VERSION ""

NS_ :

BS_:

BU_: ECU PD16A KEYPAD

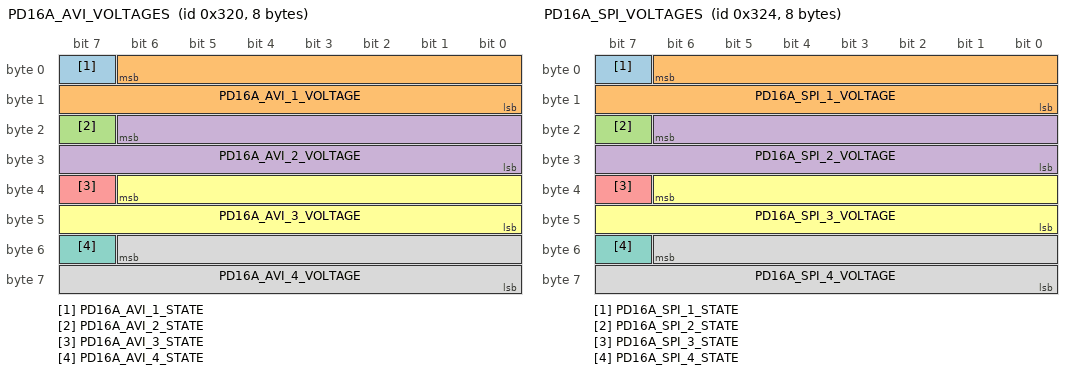
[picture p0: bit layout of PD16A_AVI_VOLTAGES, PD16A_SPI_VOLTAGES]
BO_ 800 PD16A_AVI_VOLTAGES: 8 PD16A
 SG_ PD16A_AVI_1_STATE : 7|1@0+ (1,0) [0|0] "" ECU
 SG_ PD16A_AVI_1_VOLTAGE : 6|15@0+ (0.001,0) [0|32.767] "V" ECU
 SG_ PD16A_AVI_2_STATE : 23|1@0+ (1,0) [0|0] "" ECU
 SG_ PD16A_AVI_2_VOLTAGE : 22|15@0+ (0.001,0) [0|32.767] "V" ECU
 SG_ PD16A_AVI_3_STATE : 39|1@0+ (1,0) [0|0] "" ECU
 SG_ PD16A_AVI_3_VOLTAGE : 38|15@0+ (0.001,0) [0|32.767] "V" ECU
 SG_ PD16A_AVI_4_STATE : 55|1@0+ (1,0) [0|0] "" ECU
 SG_ PD16A_AVI_4_VOLTAGE : 54|15@0+ (0.001,0) [0|32.767] "V" ECU

BO_ 804 PD16A_SPI_VOLTAGES: 8 PD16A
 SG_ PD16A_SPI_1_STATE : 7|1@0+ (1,0) [0|0] "" ECU
 SG_ PD16A_SPI_1_VOLTAGE : 6|15@0+ (0.001,0) [0|32.767] "V" ECU
 SG_ PD16A_SPI_2_STATE : 23|1@0+ (1,0) [0|0] "" ECU
 SG_ PD16A_SPI_2_VOLTAGE : 22|15@0+ (0.001,0) [0|32.767] "V" ECU
 SG_ PD16A_SPI_3_STATE : 39|1@0+ (1,0) [0|0] "" ECU
 SG_ PD16A_SPI_3_VOLTAGE : 38|15@0+ (0.001,0) [0|32.767] "V" ECU
 SG_ PD16A_SPI_4_STATE : 55|1@0+ (1,0) [0|0] "" ECU
 SG_ PD16A_SPI_4_VOLTAGE : 54|15@0+ (0.001,0) [0|32.767] "V" ECU

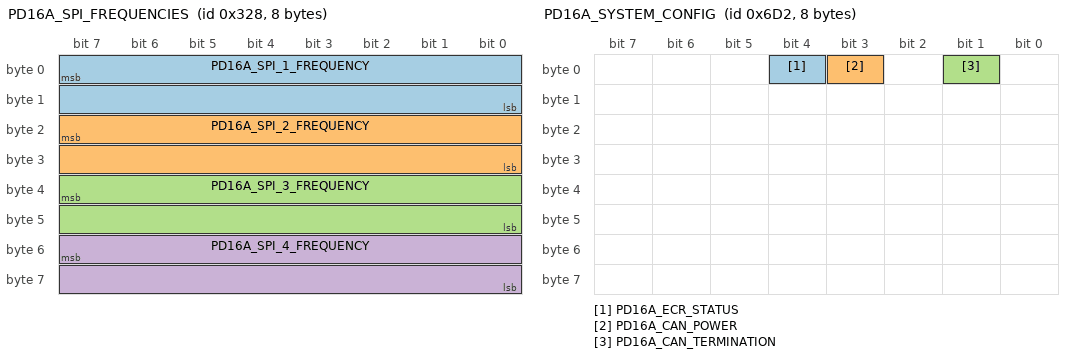
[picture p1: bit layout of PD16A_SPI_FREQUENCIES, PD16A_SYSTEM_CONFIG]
BO_ 808 PD16A_SPI_FREQUENCIES: 8 PD16A
 SG_ PD16A_SPI_1_FREQUENCY : 7|16@0+ (0.25,0) [0|16383.8] "Hz" ECU
 SG_ PD16A_SPI_2_FREQUENCY : 23|16@0+ (0.25,0) [0|16383.8] "Hz" ECU
 SG_ PD16A_SPI_3_FREQUENCY : 39|16@0+ (0.25,0) [0|16383.8] "Hz" ECU
 SG_ PD16A_SPI_4_FREQUENCY : 55|16@0+ (0.25,0) [0|16383.8] "Hz" ECU

BO_ 1744 PD16A_OUTPUT_COMMANDS: 8 ECU
 SG_ PD16A_OUTPUT_CMD_MUX M : 7|8@0+ (1,0) [0|255] "" PD16A
 SG_ PD16A_HCO25_1_CMD_DUTY m0 : 15|16@0+ (0.1,0) [0|100] "%" PD16A
 SG_ PD16A_HCO25_1_CMD_FREQ m0 : 31|16@0+ (1,0) [0|65535] "Hz" PD16A
 SG_ PD16A_HCO25_2_CMD_DUTY m1 : 15|16@0+ (0.1,0) [0|100] "%" PD16A
 SG_ PD16A_HCO25_2_CMD_FREQ m1 : 31|16@0+ (1,0) [0|65535] "Hz" PD16A
 SG_ PD16A_HCO25_3_CMD_DUTY m2 : 15|16@0+ (0.1,0) [0|100] "%" PD16A
 SG_ PD16A_HCO25_3_CMD_FREQ m2 : 31|16@0+ (1,0) [0|65535] "Hz" PD16A
 SG_ PD16A_HCO25_4_CMD_DUTY m3 : 15|16@0+ (0.1,0) [0|100] "%" PD16A
 SG_ PD16A_HCO25_4_CMD_FREQ m3 : 31|16@0+ (1,0) [0|65535] "Hz" PD16A
 SG_ PD16A_HCO8_1_CMD_DUTY m32 : 15|16@0+ (0.1,0) [0|100] "%" PD16A
 SG_ PD16A_HCO8_1_CMD_FREQ m32 : 31|16@0+ (1,0) [0|65535] "Hz" PD16A
 SG_ PD16A_HCO8_2_CMD_DUTY m33 : 15|16@0+ (0.1,0) [0|100] "%" PD16A
 SG_ PD16A_HCO8_2_CMD_FREQ m33 : 31|16@0+ (1,0) [0|65535] "Hz" PD16A
 SG_ PD16A_HCO8_3_CMD_DUTY m34 : 15|16@0+ (0.1,0) [0|100] "%" PD16A
 SG_ PD16A_HCO8_3_CMD_FREQ m34 : 31|16@0+ (1,0) [0|65535] "Hz" PD16A
 SG_ PD16A_HCO8_4_CMD_DUTY m35 : 15|16@0+ (0.1,0) [0|100] "%" PD16A
 SG_ PD16A_HCO8_4_CMD_FREQ m35 : 31|16@0+ (1,0) [0|65535] "Hz" PD16A
 SG_ PD16A_HCO8_5_CMD_DUTY m36 : 15|16@0+ (0.1,0) [0|100] "%" PD16A
 SG_ PD16A_HCO8_5_CMD_FREQ m36 : 31|16@0+ (1,0) [0|65535] "Hz" PD16A
 SG_ PD16A_HCO8_6_CMD_DUTY m37 : 15|16@0+ (0.1,0) [0|100] "%" PD16A
 SG_ PD16A_HCO8_6_CMD_FREQ m37 : 31|16@0+ (1,0) [0|65535] "Hz" PD16A
 SG_ PD16A_HCO8_7_CMD_DUTY m38 : 15|16@0+ (0.1,0) [0|100] "%" PD16A
 SG_ PD16A_HCO8_7_CMD_FREQ m38 : 31|16@0+ (1,0) [0|65535] "Hz" PD16A
 SG_ PD16A_HCO8_8_CMD_DUTY m39 : 15|16@0+ (0.1,0) [0|100] "%" PD16A
 SG_ PD16A_HCO8_8_CMD_FREQ m39 : 31|16@0+ (1,0) [0|65535] "Hz" PD16A
 SG_ PD16A_HCO8_9_CMD_DUTY m40 : 15|16@0+ (0.1,0) [0|100] "%" PD16A
 SG_ PD16A_HCO8_9_CMD_FREQ m40 : 31|16@0+ (1,0) [0|65535] "Hz" PD16A
 SG_ PD16A_HCO8_10_CMD_DUTY m41 : 15|16@0+ (0.1,0) [0|100] "%" PD16A
 SG_ PD16A_HCO8_10_CMD_FREQ m41 : 31|16@0+ (1,0) [0|65535] "Hz" PD16A
 SG_ PD16A_HBO_1_CMD_DUTY m64 : 15|16@0+ (0.1,0) [0|100] "%" PD16A
 SG_ PD16A_HBO_1_CMD_FREQ m64 : 31|16@0+ (1,0) [0|65535] "Hz" PD16A
 SG_ PD16A_HBO_1_TARGET_CURRENT m64 : 47|16@0+ (0.001,0) [0|65.535] "A" PD16A
 SG_ PD16A_HBO_2_CMD_DUTY m65 : 15|16@0+ (0.1,0) [0|100] "%" PD16A
 SG_ PD16A_HBO_2_CMD_FREQ m65 : 31|16@0+ (1,0) [0|65535] "Hz" PD16A
 SG_ PD16A_HBO_2_TARGET_CURRENT m65 : 47|16@0+ (0.001,0) [0|65.535] "A" PD16A

BO_ 1745 PD16A_IO_CONFIG: 8 ECU
 SG_ PD16A_IO_CFG_MUX M : 7|8@0+ (1,0) [0|255] "" PD16A
 SG_ PD16A_HCO25_1_CFG_RETRIES m0 : 15|3@0+ (1,0) [0|7] "" PD16A
 SG_ PD16A_HCO25_1_CFG_DRIVE_TYPE m0 : 12|2@0+ (1,0) [0|3] "" PD16A
 SG_ PD16A_HCO25_1_CFG_SAFE_STATE m0 : 10|2@0+ (1,0) [0|3] "" PD16A
 SG_ PD16A_HCO25_1_CFG_ACTIVE_STATE m0 : 8|1@0+ (1,0) [0|0] "" PD16A
 SG_ PD16A_HCO25_1_CFG_RETRY_DELAY m0 : 23|8@0+ (1,0) [0|240] "s" PD16A
 SG_ PD16A_HCO25_1_CFG_FUSE_CURRENT m0 : 31|8@0+ (0.2,0) [0|50] "A" PD16A
 SG_ PD16A_HCO25_1_CFG_SS_CURRENT m0 : 39|8@0+ (0.2,0) [0|50] "A" PD16A
 SG_ PD16A_HCO25_1_CFG_SS_DURATION m0 : 47|8@0+ (0.1,0) [0|25] "s" PD16A
 SG_ PD16A_HCO25_2_CFG_RETRIES m1 : 15|3@0+ (1,0) [0|7] "" PD16A
 SG_ PD16A_HCO25_2_CFG_DRIVE_TYPE m1 : 12|2@0+ (1,0) [0|3] "" PD16A
 SG_ PD16A_HCO25_2_CFG_SAFE_STATE m1 : 10|2@0+ (1,0) [0|3] "" PD16A
 SG_ PD16A_HCO25_2_CFG_ACTIVE_STATE m1 : 8|1@0+ (1,0) [0|0] "" PD16A
 SG_ PD16A_HCO25_2_CFG_RETRY_DELAY m1 : 23|8@0+ (1,0) [0|240] "s" PD16A
 SG_ PD16A_HCO25_2_CFG_FUSE_CURRENT m1 : 31|8@0+ (0.2,0) [0|50] "A" PD16A
 SG_ PD16A_HCO25_2_CFG_SS_CURRENT m1 : 39|8@0+ (0.2,0) [0|50] "A" PD16A
 SG_ PD16A_HCO25_2_CFG_SS_DURATION m1 : 47|8@0+ (0.1,0) [0|25] "s" PD16A
 SG_ PD16A_HCO25_3_CFG_RETRIES m2 : 15|3@0+ (1,0) [0|7] "" PD16A
 SG_ PD16A_HCO25_3_CFG_DRIVE_TYPE m2 : 12|2@0+ (1,0) [0|3] "" PD16A
 SG_ PD16A_HCO25_3_CFG_SAFE_STATE m2 : 10|2@0+ (1,0) [0|3] "" PD16A
 SG_ PD16A_HCO25_3_CFG_ACTIVE_STATE m2 : 8|1@0+ (1,0) [0|0] "" PD16A
 SG_ PD16A_HCO25_3_CFG_RETRY_DELAY m2 : 23|8@0+ (1,0) [0|240] "s" PD16A
 SG_ PD16A_HCO25_3_CFG_FUSE_CURRENT m2 : 31|8@0+ (0.2,0) [0|50] "A" PD16A
 SG_ PD16A_HCO25_3_CFG_SS_CURRENT m2 : 39|8@0+ (0.2,0) [0|50] "A" PD16A
 SG_ PD16A_HCO25_3_CFG_SS_DURATION m2 : 47|8@0+ (0.1,0) [0|25] "s" PD16A
 SG_ PD16A_HCO25_4_CFG_RETRIES m3 : 15|3@0+ (1,0) [0|7] "" PD16A
 SG_ PD16A_HCO25_4_CFG_DRIVE_TYPE m3 : 12|2@0+ (1,0) [0|3] "" PD16A
 SG_ PD16A_HCO25_4_CFG_SAFE_STATE m3 : 10|2@0+ (1,0) [0|3] "" PD16A
 SG_ PD16A_HCO25_4_CFG_ACTIVE_STATE m3 : 8|1@0+ (1,0) [0|0] "" PD16A
 SG_ PD16A_HCO25_4_CFG_RETRY_DELAY m3 : 23|8@0+ (1,0) [0|240] "s" PD16A
 SG_ PD16A_HCO25_4_CFG_FUSE_CURRENT m3 : 31|8@0+ (0.2,0) [0|50] "A" PD16A
 SG_ PD16A_HCO25_4_CFG_SS_CURRENT m3 : 39|8@0+ (0.2,0) [0|50] "A" PD16A
 SG_ PD16A_HCO25_4_CFG_SS_DURATION m3 : 47|8@0+ (0.1,0) [0|25] "s" PD16A
 SG_ PD16A_HCO8_1_CFG_RETRIES m32 : 15|3@0+ (1,0) [0|7] "" PD16A
 SG_ PD16A_HCO8_1_CFG_DRIVE_TYPE m32 : 12|2@0+ (1,0) [0|3] "" PD16A
 SG_ PD16A_HCO8_1_CFG_SAFE_STATE m32 : 10|2@0+ (1,0) [0|3] "" PD16A
 SG_ PD16A_HCO8_1_CFG_ACTIVE_STATE m32 : 8|1@0+ (1,0) [0|0] "" PD16A
 SG_ PD16A_HCO8_1_CFG_RETRY_DELAY m32 : 23|8@0+ (1,0) [0|240] "s" PD16A
 SG_ PD16A_HCO8_1_CFG_FUSE_CURRENT m32 : 31|8@0+ (0.2,0) [0|50] "A" PD16A
 SG_ PD16A_HCO8_2_CFG_RETRIES m33 : 15|3@0+ (1,0) [0|7] "" PD16A
 SG_ PD16A_HCO8_2_CFG_DRIVE_TYPE m33 : 12|2@0+ (1,0) [0|3] "" PD16A
 SG_ PD16A_HCO8_2_CFG_SAFE_STATE m33 : 10|2@0+ (1,0) [0|3] "" PD16A
 SG_ PD16A_HCO8_2_CFG_ACTIVE_STATE m33 : 8|1@0+ (1,0) [0|0] "" PD16A
 SG_ PD16A_HCO8_2_CFG_RETRY_DELAY m33 : 23|8@0+ (1,0) [0|240] "s" PD16A
 SG_ PD16A_HCO8_2_CFG_FUSE_CURRENT m33 : 31|8@0+ (0.2,0) [0|50] "A" PD16A
 SG_ PD16A_HCO8_3_CFG_RETRIES m34 : 15|3@0+ (1,0) [0|7] "" PD16A
 SG_ PD16A_HCO8_3_CFG_DRIVE_TYPE m34 : 12|2@0+ (1,0) [0|3] "" PD16A
 SG_ PD16A_HCO8_3_CFG_SAFE_STATE m34 : 10|2@0+ (1,0) [0|3] "" PD16A
 SG_ PD16A_HCO8_3_CFG_ACTIVE_STATE m34 : 8|1@0+ (1,0) [0|0] "" PD16A
 SG_ PD16A_HCO8_3_CFG_RETRY_DELAY m34 : 23|8@0+ (1,0) [0|240] "s" PD16A
 SG_ PD16A_HCO8_3_CFG_FUSE_CURRENT m34 : 31|8@0+ (0.2,0) [0|50] "A" PD16A
 SG_ PD16A_HCO8_4_CFG_RETRIES m35 : 15|3@0+ (1,0) [0|7] "" PD16A
 SG_ PD16A_HCO8_4_CFG_DRIVE_TYPE m35 : 12|2@0+ (1,0) [0|3] "" PD16A
 SG_ PD16A_HCO8_4_CFG_SAFE_STATE m35 : 10|2@0+ (1,0) [0|3] "" PD16A
 SG_ PD16A_HCO8_4_CFG_ACTIVE_STATE m35 : 8|1@0+ (1,0) [0|0] "" PD16A
 SG_ PD16A_HCO8_4_CFG_RETRY_DELAY m35 : 23|8@0+ (1,0) [0|240] "s" PD16A
 SG_ PD16A_HCO8_4_CFG_FUSE_CURRENT m35 : 31|8@0+ (0.2,0) [0|50] "A" PD16A
 SG_ PD16A_HCO8_5_CFG_RETRIES m36 : 15|3@0+ (1,0) [0|7] "" PD16A
 SG_ PD16A_HCO8_5_CFG_DRIVE_TYPE m36 : 12|2@0+ (1,0) [0|3] "" PD16A
 SG_ PD16A_HCO8_5_CFG_SAFE_STATE m36 : 10|2@0+ (1,0) [0|3] "" PD16A
 SG_ PD16A_HCO8_5_CFG_ACTIVE_STATE m36 : 8|1@0+ (1,0) [0|0] "" PD16A
 SG_ PD16A_HCO8_5_CFG_RETRY_DELAY m36 : 23|8@0+ (1,0) [0|240] "s" PD16A
 SG_ PD16A_HCO8_5_CFG_FUSE_CURRENT m36 : 31|8@0+ (0.2,0) [0|50] "A" PD16A
 SG_ PD16A_HCO8_6_CFG_RETRIES m37 : 15|3@0+ (1,0) [0|7] "" PD16A
 SG_ PD16A_HCO8_6_CFG_DRIVE_TYPE m37 : 12|2@0+ (1,0) [0|3] "" PD16A
 SG_ PD16A_HCO8_6_CFG_SAFE_STATE m37 : 10|2@0+ (1,0) [0|3] "" PD16A
 SG_ PD16A_HCO8_6_CFG_ACTIVE_STATE m37 : 8|1@0+ (1,0) [0|0] "" PD16A
 SG_ PD16A_HCO8_6_CFG_RETRY_DELAY m37 : 23|8@0+ (1,0) [0|240] "s" PD16A
 SG_ PD16A_HCO8_6_CFG_FUSE_CURRENT m37 : 31|8@0+ (0.2,0) [0|50] "A" PD16A
 SG_ PD16A_HCO8_7_CFG_RETRIES m38 : 15|3@0+ (1,0) [0|7] "" PD16A
 SG_ PD16A_HCO8_7_CFG_DRIVE_TYPE m38 : 12|2@0+ (1,0) [0|3] "" PD16A
 SG_ PD16A_HCO8_7_CFG_SAFE_STATE m38 : 10|2@0+ (1,0) [0|3] "" PD16A
 SG_ PD16A_HCO8_7_CFG_ACTIVE_STATE m38 : 8|1@0+ (1,0) [0|0] "" PD16A
 SG_ PD16A_HCO8_7_CFG_RETRY_DELAY m38 : 23|8@0+ (1,0) [0|240] "s" PD16A
 SG_ PD16A_HCO8_7_CFG_FUSE_CURRENT m38 : 31|8@0+ (0.2,0) [0|50] "A" PD16A
 SG_ PD16A_HCO8_8_CFG_RETRIES m39 : 15|3@0+ (1,0) [0|7] "" PD16A
 SG_ PD16A_HCO8_8_CFG_DRIVE_TYPE m39 : 12|2@0+ (1,0) [0|3] "" PD16A
 SG_ PD16A_HCO8_8_CFG_SAFE_STATE m39 : 10|2@0+ (1,0) [0|3] "" PD16A
 SG_ PD16A_HCO8_8_CFG_ACTIVE_STATE m39 : 8|1@0+ (1,0) [0|0] "" PD16A
 SG_ PD16A_HCO8_8_CFG_RETRY_DELAY m39 : 23|8@0+ (1,0) [0|240] "s" PD16A
 SG_ PD16A_HCO8_8_CFG_FUSE_CURRENT m39 : 31|8@0+ (0.2,0) [0|50] "A" PD16A
 SG_ PD16A_HCO8_9_CFG_RETRIES m40 : 15|3@0+ (1,0) [0|7] "" PD16A
 SG_ PD16A_HCO8_9_CFG_DRIVE_TYPE m40 : 12|2@0+ (1,0) [0|3] "" PD16A
 SG_ PD16A_HCO8_9_CFG_SAFE_STATE m40 : 10|2@0+ (1,0) [0|3] "" PD16A
 SG_ PD16A_HCO8_9_CFG_ACTIVE_STATE m40 : 8|1@0+ (1,0) [0|0] "" PD16A
 SG_ PD16A_HCO8_9_CFG_RETRY_DELAY m40 : 23|8@0+ (1,0) [0|240] "s" PD16A
 SG_ PD16A_HCO8_9_CFG_FUSE_CURRENT m40 : 31|8@0+ (0.2,0) [0|50] "A" PD16A
 SG_ PD16A_HCO8_10_CFG_RETRIES m41 : 15|3@0+ (1,0) [0|7] "" PD16A
 SG_ PD16A_HCO8_10_CFG_DRIVE_TYPE m41 : 12|2@0+ (1,0) [0|3] "" PD16A
 SG_ PD16A_HCO8_10_CFG_SAFE_STATE m41 : 10|2@0+ (1,0) [0|3] "" PD16A
 SG_ PD16A_HCO8_10_CFG_ACTIVE_STATE m41 : 8|1@0+ (1,0) [0|0] "" PD16A
 SG_ PD16A_HCO8_10_CFG_RETRY_DELAY m41 : 23|8@0+ (1,0) [0|240] "s" PD16A
 SG_ PD16A_HCO8_10_CFG_FUSE_CURRENT m41 : 31|8@0+ (0.2,0) [0|50] "A" PD16A
 SG_ PD16A_HBO_1_CFG_RETRIES m64 : 15|3@0+ (1,0) [0|7] "" PD16A
 SG_ PD16A_HBO_1_CFG_DRIVE_TYPE m64 : 12|2@0+ (1,0) [0|3] "" PD16A
 SG_ PD16A_HBO_1_CFG_SAFE_STATE m64 : 10|2@0+ (1,0) [0|3] "" PD16A
 SG_ PD16A_HBO_1_CFG_ACTIVE_STATE m64 : 8|1@0+ (1,0) [0|0] "" PD16A
 SG_ PD16A_HBO_1_CFG_RETRY_DELAY m64 : 23|8@0+ (1,0) [0|240] "s" PD16A
 SG_ PD16A_HBO_1_CFG_CONTROL_METHOD m64 : 24|1@0+ (1,0) [0|0] "" PD16A
 SG_ PD16A_HBO_1_CFG_FUSE_CURRENT m64 : 39|8@0+ (0.2,0) [0|50] "A" PD16A
 SG_ PD16A_HBO_2_CFG_RETRIES m65 : 15|3@0+ (1,0) [0|7] "" PD16A
 SG_ PD16A_HBO_2_CFG_DRIVE_TYPE m65 : 12|2@0+ (1,0) [0|3] "" PD16A
 SG_ PD16A_HBO_2_CFG_SAFE_STATE m65 : 10|2@0+ (1,0) [0|3] "" PD16A
 SG_ PD16A_HBO_2_CFG_ACTIVE_STATE m65 : 8|1@0+ (1,0) [0|0] "" PD16A
 SG_ PD16A_HBO_2_CFG_RETRY_DELAY m65 : 23|8@0+ (1,0) [0|240] "s" PD16A
 SG_ PD16A_HBO_2_CFG_CONTROL_METHOD m65 : 24|1@0+ (1,0) [0|0] "" PD16A
 SG_ PD16A_HBO_2_CFG_FUSE_CURRENT m65 : 39|8@0+ (0.2,0) [0|50] "A" PD16A
 SG_ PD16A_SPI_1_CFG_PIN_MODE m96 : 15|2@0+ (1,0) [0|2] "" PD16A
 SG_ PD16A_SPI_1_CFG_STARTUP_STATE m96 : 13|2@0+ (1,0) [0|2] "" PD16A
 SG_ PD16A_SPI_1_CFG_INPUT_MODE m96 : 11|1@0+ (1,0) [0|0] "" PD16A
 SG_ PD16A_SPI_1_CFG_PULLUP m96 : 10|2@0+ (1,0) [0|1] "" PD16A
 SG_ PD16A_SPI_1_CFG_EDGE_SELECT m96 : 8|1@0+ (1,0) [0|0] "" PD16A
 SG_ PD16A_SPI_1_CFG_UPPER_THRESHOLD m96 : 39|16@0+ (0.001,0) [0|65.535] "V" PD16A
 SG_ PD16A_SPI_1_CFG_GLITCH_FILTER m96 : 55|16@0+ (1,0) [0|500] "us" PD16A
 SG_ PD16A_SPI_2_CFG_PIN_MODE m97 : 15|2@0+ (1,0) [0|2] "" PD16A
 SG_ PD16A_SPI_2_CFG_STARTUP_STATE m97 : 13|2@0+ (1,0) [0|2] "" PD16A
 SG_ PD16A_SPI_2_CFG_INPUT_MODE m97 : 11|1@0+ (1,0) [0|0] "" PD16A
 SG_ PD16A_SPI_2_CFG_PULLUP m97 : 10|2@0+ (1,0) [0|1] "" PD16A
 SG_ PD16A_SPI_2_CFG_EDGE_SELECT m97 : 8|1@0+ (1,0) [0|0] "" PD16A
 SG_ PD16A_SPI_2_CFG_UPPER_THRESHOLD m97 : 39|16@0+ (0.001,0) [0|65.535] "V" PD16A
 SG_ PD16A_SPI_2_CFG_GLITCH_FILTER m97 : 55|16@0+ (1,0) [0|500] "us" PD16A
 SG_ PD16A_SPI_3_CFG_PIN_MODE m98 : 15|2@0+ (1,0) [0|2] "" PD16A
 SG_ PD16A_SPI_3_CFG_STARTUP_STATE m98 : 13|2@0+ (1,0) [0|2] "" PD16A
 SG_ PD16A_SPI_3_CFG_INPUT_MODE m98 : 11|1@0+ (1,0) [0|0] "" PD16A
 SG_ PD16A_SPI_3_CFG_PULLUP m98 : 10|2@0+ (1,0) [0|1] "" PD16A
 SG_ PD16A_SPI_3_CFG_EDGE_SELECT m98 : 8|1@0+ (1,0) [0|0] "" PD16A
 SG_ PD16A_SPI_3_CFG_UPPER_THRESHOLD m98 : 39|16@0+ (0.001,0) [0|65.535] "V" PD16A
 SG_ PD16A_SPI_3_CFG_GLITCH_FILTER m98 : 55|16@0+ (1,0) [0|500] "us" PD16A
 SG_ PD16A_SPI_4_CFG_PIN_MODE m99 : 15|2@0+ (1,0) [0|2] "" PD16A
 SG_ PD16A_SPI_4_CFG_STARTUP_STATE m99 : 13|2@0+ (1,0) [0|2] "" PD16A
 SG_ PD16A_SPI_4_CFG_INPUT_MODE m99 : 11|1@0+ (1,0) [0|0] "" PD16A
 SG_ PD16A_SPI_4_CFG_PULLUP m99 : 10|2@0+ (1,0) [0|1] "" PD16A
 SG_ PD16A_SPI_4_CFG_EDGE_SELECT m99 : 8|1@0+ (1,0) [0|0] "" PD16A
 SG_ PD16A_SPI_4_CFG_UPPER_THRESHOLD m99 : 39|16@0+ (0.001,0) [0|65.535] "V" PD16A
 SG_ PD16A_SPI_4_CFG_GLITCH_FILTER m99 : 55|16@0+ (1,0) [0|500] "us" PD16A
 SG_ PD16A_AVI_1_CFG_STARTUP_STATE m128 : 13|2@0+ (1,0) [0|2] "" PD16A
 SG_ PD16A_AVI_1_CFG_INPUT_MODE m128 : 11|1@0+ (1,0) [0|0] "" PD16A
 SG_ PD16A_AVI_1_CFG_PULLUP m128 : 10|2@0+ (1,0) [0|2] "" PD16A
 SG_ PD16A_AVI_1_CFG_ON_THRESHOLD m128 : 23|16@0+ (0.001,0) [0|65.535] "V" PD16A
 SG_ PD16A_AVI_1_CFG_OFF_THRESHOLD m128 : 39|16@0+ (0.001,0) [0|65.535] "V" PD16A
 SG_ PD16A_AVI_2_CFG_STARTUP_STATE m129 : 13|2@0+ (1,0) [0|2] "" PD16A
 SG_ PD16A_AVI_2_CFG_INPUT_MODE m129 : 11|1@0+ (1,0) [0|0] "" PD16A
 SG_ PD16A_AVI_2_CFG_PULLUP m129 : 10|2@0+ (1,0) [0|2] "" PD16A
 SG_ PD16A_AVI_2_CFG_ON_THRESHOLD m129 : 23|16@0+ (0.001,0) [0|65.535] "V" PD16A
 SG_ PD16A_AVI_2_CFG_OFF_THRESHOLD m129 : 39|16@0+ (0.001,0) [0|65.535] "V" PD16A
 SG_ PD16A_AVI_3_CFG_STARTUP_STATE m130 : 13|2@0+ (1,0) [0|2] "" PD16A
 SG_ PD16A_AVI_3_CFG_INPUT_MODE m130 : 11|1@0+ (1,0) [0|0] "" PD16A
 SG_ PD16A_AVI_3_CFG_PULLUP m130 : 10|2@0+ (1,0) [0|2] "" PD16A
 SG_ PD16A_AVI_3_CFG_ON_THRESHOLD m130 : 23|16@0+ (0.001,0) [0|65.535] "V" PD16A
 SG_ PD16A_AVI_3_CFG_OFF_THRESHOLD m130 : 39|16@0+ (0.001,0) [0|65.535] "V" PD16A
 SG_ PD16A_AVI_4_CFG_STARTUP_STATE m131 : 13|2@0+ (1,0) [0|2] "" PD16A
 SG_ PD16A_AVI_4_CFG_INPUT_MODE m131 : 11|1@0+ (1,0) [0|0] "" PD16A
 SG_ PD16A_AVI_4_CFG_PULLUP m131 : 10|2@0+ (1,0) [0|2] "" PD16A
 SG_ PD16A_AVI_4_CFG_ON_THRESHOLD m131 : 23|16@0+ (0.001,0) [0|65.535] "V" PD16A
 SG_ PD16A_AVI_4_CFG_OFF_THRESHOLD m131 : 39|16@0+ (0.001,0) [0|65.535] "V" PD16A

BO_ 1746 PD16A_SYSTEM_CONFIG: 8 ECU
 SG_ PD16A_ECR_STATUS : 4|1@0+ (1,0) [0|0] "" PD16A
 SG_ PD16A_CAN_POWER : 3|1@0+ (1,0) [0|0] "" PD16A
 SG_ PD16A_CAN_TERMINATION : 1|1@0+ (1,0) [0|0] "" PD16A

BO_ 1747 PD16A_INPUT_STATUS: 8 PD16A
 SG_ PD16A_INPUT_STATUS_MUX M : 7|8@0+ (1,0) [0|255] "" ECU
 SG_ PD16A_SPI_1_IN_STATE m96 : 8|1@0+ (1,0) [0|0] "" ECU
 SG_ PD16A_SPI_1_IN_VOLTAGE m96 : 23|16@0+ (0.001,0) [0|65.535] "V" ECU
 SG_ PD16A_SPI_1_IN_DUTY m96 : 39|16@0+ (0.1,0) [0|100] "%" ECU
 SG_ PD16A_SPI_1_IN_FREQUENCY m96 : 55|16@0+ (1,0) [0|65535] "Hz" ECU
 SG_ PD16A_SPI_2_IN_STATE m97 : 8|1@0+ (1,0) [0|0] "" ECU
 SG_ PD16A_SPI_2_IN_VOLTAGE m97 : 23|16@0+ (0.001,0) [0|65.535] "V" ECU
 SG_ PD16A_SPI_2_IN_DUTY m97 : 39|16@0+ (0.1,0) [0|100] "%" ECU
 SG_ PD16A_SPI_2_IN_FREQUENCY m97 : 55|16@0+ (1,0) [0|65535] "Hz" ECU
 SG_ PD16A_SPI_3_IN_STATE m98 : 8|1@0+ (1,0) [0|0] "" ECU
 SG_ PD16A_SPI_3_IN_VOLTAGE m98 : 23|16@0+ (0.001,0) [0|65.535] "V" ECU
 SG_ PD16A_SPI_3_IN_DUTY m98 : 39|16@0+ (0.1,0) [0|100] "%" ECU
 SG_ PD16A_SPI_3_IN_FREQUENCY m98 : 55|16@0+ (1,0) [0|65535] "Hz" ECU
 SG_ PD16A_SPI_4_IN_STATE m99 : 8|1@0+ (1,0) [0|0] "" ECU
 SG_ PD16A_SPI_4_IN_VOLTAGE m99 : 23|16@0+ (0.001,0) [0|65.535] "V" ECU
 SG_ PD16A_SPI_4_IN_DUTY m99 : 39|16@0+ (0.1,0) [0|100] "%" ECU
 SG_ PD16A_SPI_4_IN_FREQUENCY m99 : 55|16@0+ (1,0) [0|65535] "Hz" ECU
 SG_ PD16A_AVI_1_IN_STATE m128 : 8|1@0+ (1,0) [0|0] "" ECU
 SG_ PD16A_AVI_1_IN_VOLTAGE m128 : 23|16@0+ (0.001,0) [0|65.535] "V" ECU
 SG_ PD16A_AVI_2_IN_STATE m129 : 8|1@0+ (1,0) [0|0] "" ECU
 SG_ PD16A_AVI_2_IN_VOLTAGE m129 : 23|16@0+ (0.001,0) [0|65.535] "V" ECU
 SG_ PD16A_AVI_3_IN_STATE m130 : 8|1@0+ (1,0) [0|0] "" ECU
 SG_ PD16A_AVI_3_IN_VOLTAGE m130 : 23|16@0+ (0.001,0) [0|65.535] "V" ECU
 SG_ PD16A_AVI_4_IN_STATE m131 : 8|1@0+ (1,0) [0|0] "" ECU
 SG_ PD16A_AVI_4_IN_VOLTAGE m131 : 23|16@0+ (0.001,0) [0|65.535] "V" ECU

BO_ 1748 PD16A_OUTPUT_STATUS: 8 PD16A
 SG_ PD16A_OUTPUT_STATUS_MUX M : 7|8@0+ (1,0) [0|255] "" ECU
 SG_ PD16A_HCO25_1_LOAD m0 : 15|8@0+ (1,0) [0|100] "%" ECU
 SG_ PD16A_HCO25_1_VOLTAGE m0 : 23|16@0+ (0.001,0) [0|65.535] "V" ECU
 SG_ PD16A_HCO25_1_LS_CURRENT m0 : 39|16@0+ (0.001,0) [0|65.535] "A" ECU
 SG_ PD16A_HCO25_1_HS_CURRENT m0 : 55|16@0+ (0.001,0) [0|65.535] "A" ECU
 SG_ PD16A_HCO25_2_LOAD m1 : 15|8@0+ (1,0) [0|100] "%" ECU
 SG_ PD16A_HCO25_2_VOLTAGE m1 : 23|16@0+ (0.001,0) [0|65.535] "V" ECU
 SG_ PD16A_HCO25_2_LS_CURRENT m1 : 39|16@0+ (0.001,0) [0|65.535] "A" ECU
 SG_ PD16A_HCO25_2_HS_CURRENT m1 : 55|16@0+ (0.001,0) [0|65.535] "A" ECU
 SG_ PD16A_HCO25_3_LOAD m2 : 15|8@0+ (1,0) [0|100] "%" ECU
 SG_ PD16A_HCO25_3_VOLTAGE m2 : 23|16@0+ (0.001,0) [0|65.535] "V" ECU
 SG_ PD16A_HCO25_3_LS_CURRENT m2 : 39|16@0+ (0.001,0) [0|65.535] "A" ECU
 SG_ PD16A_HCO25_3_HS_CURRENT m2 : 55|16@0+ (0.001,0) [0|65.535] "A" ECU
 SG_ PD16A_HCO25_4_LOAD m3 : 15|8@0+ (1,0) [0|100] "%" ECU
 SG_ PD16A_HCO25_4_VOLTAGE m3 : 23|16@0+ (0.001,0) [0|65.535] "V" ECU
 SG_ PD16A_HCO25_4_LS_CURRENT m3 : 39|16@0+ (0.001,0) [0|65.535] "A" ECU
 SG_ PD16A_HCO25_4_HS_CURRENT m3 : 55|16@0+ (0.001,0) [0|65.535] "A" ECU
 SG_ PD16A_HCO8_1_RETRY_COUNT m32 : 15|5@0+ (1,0) [0|31] "" ECU
 SG_ PD16A_HCO8_1_PIN_STATE m32 : 10|3@0+ (1,0) [0|7] "" ECU
 SG_ PD16A_HCO8_1_VOLTAGE m32 : 23|16@0+ (0.001,0) [0|65.535] "V" ECU
 SG_ PD16A_HCO8_1_CURRENT m32 : 39|16@0+ (0.001,0) [0|65.535] "A" ECU
 SG_ PD16A_HCO8_1_LOAD m32 : 55|8@0+ (1,0) [0|100] "%" ECU
 SG_ PD16A_HCO25_1_RETRY_COUNT m32 : 63|5@0+ (1,0) [0|31] "" ECU
 SG_ PD16A_HCO25_1_PIN_STATE m32 : 58|3@0+ (1,0) [0|7] "" ECU
 SG_ PD16A_HCO8_2_RETRY_COUNT m33 : 15|5@0+ (1,0) [0|31] "" ECU
 SG_ PD16A_HCO8_2_PIN_STATE m33 : 10|3@0+ (1,0) [0|7] "" ECU
 SG_ PD16A_HCO8_2_VOLTAGE m33 : 23|16@0+ (0.001,0) [0|65.535] "V" ECU
 SG_ PD16A_HCO8_2_CURRENT m33 : 39|16@0+ (0.001,0) [0|65.535] "A" ECU
 SG_ PD16A_HCO8_2_LOAD m33 : 55|8@0+ (1,0) [0|100] "%" ECU
 SG_ PD16A_HCO25_2_RETRY_COUNT m33 : 63|5@0+ (1,0) [0|31] "" ECU
 SG_ PD16A_HCO25_2_PIN_STATE m33 : 58|3@0+ (1,0) [0|7] "" ECU
 SG_ PD16A_HCO8_3_RETRY_COUNT m34 : 15|5@0+ (1,0) [0|31] "" ECU
 SG_ PD16A_HCO8_3_PIN_STATE m34 : 10|3@0+ (1,0) [0|7] "" ECU
 SG_ PD16A_HCO8_3_VOLTAGE m34 : 23|16@0+ (0.001,0) [0|65.535] "V" ECU
 SG_ PD16A_HCO8_3_CURRENT m34 : 39|16@0+ (0.001,0) [0|65.535] "A" ECU
 SG_ PD16A_HCO8_3_LOAD m34 : 55|8@0+ (1,0) [0|100] "%" ECU
 SG_ PD16A_HCO25_3_RETRY_COUNT m34 : 63|5@0+ (1,0) [0|31] "" ECU
 SG_ PD16A_HCO25_3_PIN_STATE m34 : 58|3@0+ (1,0) [0|7] "" ECU
 SG_ PD16A_HCO8_4_RETRY_COUNT m35 : 15|5@0+ (1,0) [0|31] "" ECU
 SG_ PD16A_HCO8_4_PIN_STATE m35 : 10|3@0+ (1,0) [0|7] "" ECU
 SG_ PD16A_HCO8_4_VOLTAGE m35 : 23|16@0+ (0.001,0) [0|65.535] "V" ECU
 SG_ PD16A_HCO8_4_CURRENT m35 : 39|16@0+ (0.001,0) [0|65.535] "A" ECU
 SG_ PD16A_HCO8_4_LOAD m35 : 55|8@0+ (1,0) [0|100] "%" ECU
 SG_ PD16A_HCO25_4_RETRY_COUNT m35 : 63|5@0+ (1,0) [0|31] "" ECU
 SG_ PD16A_HCO25_4_PIN_STATE m35 : 58|3@0+ (1,0) [0|7] "" ECU
 SG_ PD16A_HCO8_5_RETRY_COUNT m36 : 15|5@0+ (1,0) [0|31] "" ECU
 SG_ PD16A_HCO8_5_PIN_STATE m36 : 10|3@0+ (1,0) [0|7] "" ECU
 SG_ PD16A_HCO8_5_VOLTAGE m36 : 23|16@0+ (0.001,0) [0|65.535] "V" ECU
 SG_ PD16A_HCO8_5_CURRENT m36 : 39|16@0+ (0.001,0) [0|65.535] "A" ECU
 SG_ PD16A_HCO8_5_LOAD m36 : 55|8@0+ (1,0) [0|100] "%" ECU
 SG_ PD16A_HCO8_6_RETRY_COUNT m37 : 15|5@0+ (1,0) [0|31] "" ECU
 SG_ PD16A_HCO8_6_PIN_STATE m37 : 10|3@0+ (1,0) [0|7] "" ECU
 SG_ PD16A_HCO8_6_VOLTAGE m37 : 23|16@0+ (0.001,0) [0|65.535] "V" ECU
 SG_ PD16A_HCO8_6_CURRENT m37 : 39|16@0+ (0.001,0) [0|65.535] "A" ECU
 SG_ PD16A_HCO8_6_LOAD m37 : 55|8@0+ (1,0) [0|100] "%" ECU
 SG_ PD16A_HCO8_7_RETRY_COUNT m38 : 15|5@0+ (1,0) [0|31] "" ECU
 SG_ PD16A_HCO8_7_PIN_STATE m38 : 10|3@0+ (1,0) [0|7] "" ECU
 SG_ PD16A_HCO8_7_VOLTAGE m38 : 23|16@0+ (0.001,0) [0|65.535] "V" ECU
 SG_ PD16A_HCO8_7_CURRENT m38 : 39|16@0+ (0.001,0) [0|65.535] "A" ECU
 SG_ PD16A_HCO8_7_LOAD m38 : 55|8@0+ (1,0) [0|100] "%" ECU
 SG_ PD16A_HCO8_8_RETRY_COUNT m39 : 15|5@0+ (1,0) [0|31] "" ECU
 SG_ PD16A_HCO8_8_PIN_STATE m39 : 10|3@0+ (1,0) [0|7] "" ECU
 SG_ PD16A_HCO8_8_VOLTAGE m39 : 23|16@0+ (0.001,0) [0|65.535] "V" ECU
 SG_ PD16A_HCO8_8_CURRENT m39 : 39|16@0+ (0.001,0) [0|65.535] "A" ECU
 SG_ PD16A_HCO8_8_LOAD m39 : 55|8@0+ (1,0) [0|100] "%" ECU
 SG_ PD16A_HCO8_9_RETRY_COUNT m40 : 15|5@0+ (1,0) [0|31] "" ECU
 SG_ PD16A_HCO8_9_PIN_STATE m40 : 10|3@0+ (1,0) [0|7] "" ECU
 SG_ PD16A_HCO8_9_VOLTAGE m40 : 23|16@0+ (0.001,0) [0|65.535] "V" ECU
 SG_ PD16A_HCO8_9_CURRENT m40 : 39|16@0+ (0.001,0) [0|65.535] "A" ECU
 SG_ PD16A_HCO8_9_LOAD m40 : 55|8@0+ (1,0) [0|100] "%" ECU
 SG_ PD16A_HCO8_10_RETRY_COUNT m41 : 15|5@0+ (1,0) [0|31] "" ECU
 SG_ PD16A_HCO8_10_PIN_STATE m41 : 10|3@0+ (1,0) [0|7] "" ECU
 SG_ PD16A_HCO8_10_VOLTAGE m41 : 23|16@0+ (0.001,0) [0|65.535] "V" ECU
 SG_ PD16A_HCO8_10_CURRENT m41 : 39|16@0+ (0.001,0) [0|65.535] "A" ECU
 SG_ PD16A_HCO8_10_LOAD m41 : 55|8@0+ (1,0) [0|100] "%" ECU
 SG_ PD16A_HBO_1_RETRY_COUNT m64 : 15|5@0+ (1,0) [0|31] "" ECU
 SG_ PD16A_HBO_1_PIN_STATE m64 : 10|3@0+ (1,0) [0|7] "" ECU
 SG_ PD16A_HBO_1_VOLTAGE m64 : 23|16@0+ (0.001,0) [0|65.535] "V" ECU
 SG_ PD16A_HBO_1_LOAD m64 : 39|8@0+ (1,0) [0|100] "%" ECU
 SG_ PD16A_HBO_1_HS_CURRENT m64 : 55|16@0+ (0.001,0) [0|65.535] "A" ECU
 SG_ PD16A_HBO_2_RETRY_COUNT m65 : 15|5@0+ (1,0) [0|31] "" ECU
 SG_ PD16A_HBO_2_PIN_STATE m65 : 10|3@0+ (1,0) [0|7] "" ECU
 SG_ PD16A_HBO_2_VOLTAGE m65 : 23|16@0+ (0.001,0) [0|65.535] "V" ECU
 SG_ PD16A_HBO_2_LOAD m65 : 39|8@0+ (1,0) [0|100] "%" ECU
 SG_ PD16A_HBO_2_HS_CURRENT m65 : 55|16@0+ (0.001,0) [0|65.535] "A" ECU

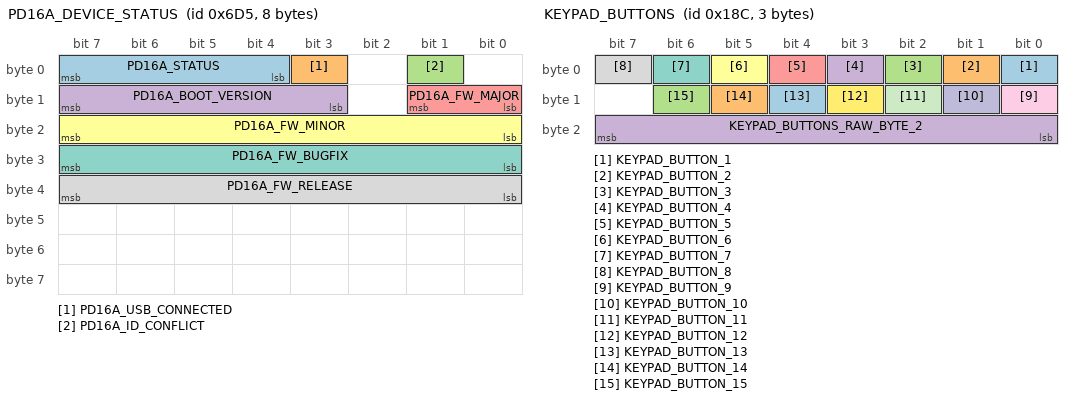
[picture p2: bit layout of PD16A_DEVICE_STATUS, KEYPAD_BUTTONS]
BO_ 1749 PD16A_DEVICE_STATUS: 8 PD16A
 SG_ PD16A_STATUS : 7|4@0+ (1,0) [0|15] "" ECU
 SG_ PD16A_USB_CONNECTED : 3|1@0+ (1,0) [0|0] "" ECU
 SG_ PD16A_ID_CONFLICT : 1|1@0+ (1,0) [0|0] "" ECU
 SG_ PD16A_BOOT_VERSION : 15|5@0+ (1,0) [0|31] "" ECU
 SG_ PD16A_FW_MAJOR : 9|2@0+ (1,0) [0|3] "" ECU
 SG_ PD16A_FW_MINOR : 23|8@0+ (1,0) [0|255] "" ECU
 SG_ PD16A_FW_BUGFIX : 31|8@0+ (1,0) [0|255] "" ECU
 SG_ PD16A_FW_RELEASE : 39|8@0+ (1,0) [0|255] "" ECU

BO_ 1750 PD16A_DIAGNOSTICS: 8 PD16A
 SG_ PD16A_DIAG_MUX M : 7|8@0+ (1,0) [0|255] "" ECU
 SG_ PD16A_IGNITION_SWITCH m0 : 8|1@0+ (1,0) [0|0] "" ECU
 SG_ PD16A_MAIN_RAIL_VOLTAGE m0 : 23|16@0+ (0.001,0) [0|65.535] "V" ECU
 SG_ PD16A_PROT_RAIL_VOLTAGE m0 : 39|16@0+ (0.001,0) [0|65.535] "V" ECU
 SG_ PD16A_ECR_PLUG_VOLTAGE m0 : 55|16@0+ (0.001,0) [0|65.535] "V" ECU
 SG_ PD16A_BOOST_VOLTAGE m1 : 23|16@0+ (0.001,0) [0|65.535] "V" ECU
 SG_ PD16A_SEPIC_VOLTAGE m1 : 39|16@0+ (0.001,0) [0|65.535] "V" ECU
 SG_ PD16A_ECR_PLUG_CURRENT m1 : 55|16@0+ (0.001,0) [0|65.535] "A" ECU
 SG_ PD16A_UVLO_VOLTAGE m2 : 23|16@0+ (0.001,0) [0|65.535] "V" ECU
 SG_ PD16A_SENSOR_GND_VOLTAGE m2 : 39|16@0+ (0.001,0) [0|65.535] "V" ECU
 SG_ PD16A_VDD_VOLTAGE m2 : 55|16@0+ (0.001,0) [0|65.535] "V" ECU
 SG_ PD16A_MAIN_RAIL_TEMP m3 : 15|8@0+ (1,0) [0|255] "degC" ECU
 SG_ PD16A_THERMISTOR_1_TEMP m3 : 23|8@0+ (1,0) [0|255] "degC" ECU
 SG_ PD16A_THERMISTOR_2_TEMP m3 : 31|8@0+ (1,0) [0|255] "degC" ECU
 SG_ PD16A_THERMISTOR_3_TEMP m3 : 39|8@0+ (1,0) [0|255] "degC" ECU
 SG_ PD16A_CPU_TEMP m3 : 47|8@0+ (1,0) [0|255] "degC" ECU
 SG_ PD16A_TOTAL_CURRENT m3 : 55|16@0+ (0.1,0) [0|6553.5] "A" ECU
 SG_ PD16A_BATTERY_VOLTAGE m4 : 23|16@0+ (0.001,0) [0|65.535] "V" ECU
 SG_ PD16A_ON_TIME m4 : 39|16@0+ (1,0) [0|65535] "s" ECU
 SG_ PD16A_HCO25_34_TEMP_STATUS m4 : 55|2@0+ (1,0) [0|3] "" ECU
 SG_ PD16A_HCO25_12_TEMP_STATUS m4 : 53|2@0+ (1,0) [0|3] "" ECU
 SG_ PD16A_TVS_TEMP_STATUS m4 : 51|2@0+ (1,0) [0|3] "" ECU
 SG_ PD16A_MAIN_RAIL_TEMP_STATUS m4 : 49|2@0+ (1,0) [0|3] "" ECU
 SG_ PD16A_SERIAL_NUMBER_BCD m5 : 23|48@0+ (1,0) [0|0] "" ECU

BO_ 396 KEYPAD_BUTTONS: 3 KEYPAD
 SG_ KEYPAD_BUTTON_1 : 0|1@1+ (1,0) [0|0] "" ECU
 SG_ KEYPAD_BUTTON_2 : 1|1@1+ (1,0) [0|0] "" ECU
 SG_ KEYPAD_BUTTON_3 : 2|1@1+ (1,0) [0|0] "" ECU
 SG_ KEYPAD_BUTTON_4 : 3|1@1+ (1,0) [0|0] "" ECU
 SG_ KEYPAD_BUTTON_5 : 4|1@1+ (1,0) [0|0] "" ECU
 SG_ KEYPAD_BUTTON_6 : 5|1@1+ (1,0) [0|0] "" ECU
 SG_ KEYPAD_BUTTON_7 : 6|1@1+ (1,0) [0|0] "" ECU
 SG_ KEYPAD_BUTTON_8 : 7|1@1+ (1,0) [0|0] "" ECU
 SG_ KEYPAD_BUTTON_9 : 8|1@1+ (1,0) [0|0] "" ECU
 SG_ KEYPAD_BUTTON_10 : 9|1@1+ (1,0) [0|0] "" ECU
 SG_ KEYPAD_BUTTON_11 : 10|1@1+ (1,0) [0|0] "" ECU
 SG_ KEYPAD_BUTTON_12 : 11|1@1+ (1,0) [0|0] "" ECU
 SG_ KEYPAD_BUTTON_13 : 12|1@1+ (1,0) [0|0] "" ECU
 SG_ KEYPAD_BUTTON_14 : 13|1@1+ (1,0) [0|0] "" ECU
 SG_ KEYPAD_BUTTON_15 : 14|1@1+ (1,0) [0|0] "" ECU
 SG_ KEYPAD_BUTTONS_RAW_BYTE_2 : 16|8@1+ (1,0) [0|255] "" ECU

BO_ 1804 KEYPAD_HEARTBEAT: 1 KEYPAD
 SG_ KEYPAD_NMT_STATE : 0|8@1+ (1,0) [0|255] "" ECU

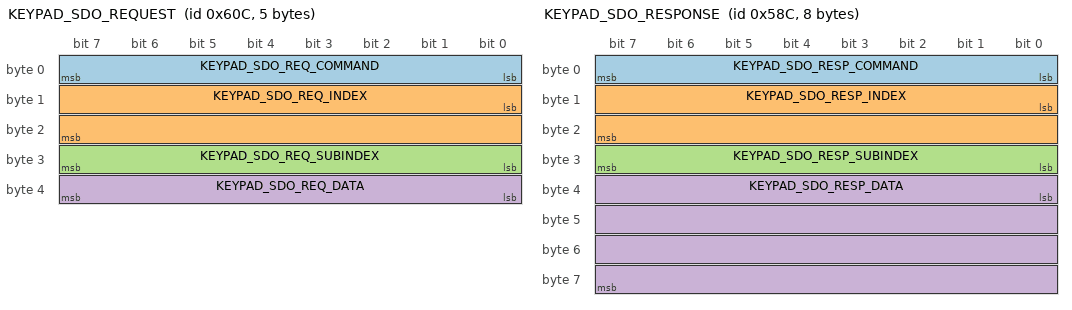
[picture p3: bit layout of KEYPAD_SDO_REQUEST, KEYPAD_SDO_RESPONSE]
BO_ 1548 KEYPAD_SDO_REQUEST: 5 ECU
 SG_ KEYPAD_SDO_REQ_COMMAND : 0|8@1+ (1,0) [0|255] "" KEYPAD
 SG_ KEYPAD_SDO_REQ_INDEX : 8|16@1+ (1,0) [0|65535] "" KEYPAD
 SG_ KEYPAD_SDO_REQ_SUBINDEX : 24|8@1+ (1,0) [0|255] "" KEYPAD
 SG_ KEYPAD_SDO_REQ_DATA : 32|8@1+ (1,0) [0|255] "" KEYPAD

BO_ 1420 KEYPAD_SDO_RESPONSE: 8 KEYPAD
 SG_ KEYPAD_SDO_RESP_COMMAND : 0|8@1+ (1,0) [0|255] "" ECU
 SG_ KEYPAD_SDO_RESP_INDEX : 8|16@1+ (1,0) [0|65535] "" ECU
 SG_ KEYPAD_SDO_RESP_SUBINDEX : 24|8@1+ (1,0) [0|255] "" ECU
 SG_ KEYPAD_SDO_RESP_DATA : 32|32@1+ (1,0) [0|4.29497e+09] "" ECU

CM_ BU_ PD16A "Haltech Nexus PD16 power distribution module, box A (base CAN ID 0x6D0). Other boxes shift the base: B=0x6D8, C=0x6E0, D=0x6E8 and inputs to 0x321/0x325/0x329 etc.";
CM_ BU_ KEYPAD "Haltech 15-button (3x5) CAN keypad, CANopen node ID 12. ECU also polls node IDs 10, 11 and 13 (0x60A/0x60B/0x60D) for keypads that are not fitted; those IDs are left undecoded.";
CM_ BO_ 800 "PD16 A AVI 1-4 switch state and pin voltage, 100Hz. Haltech Multiplexed CAN Protocol v2.0.";
CM_ BO_ 804 "PD16 A SPI 1-4 switch state and pin voltage, 100Hz.";
CM_ BO_ 808 "PD16 A SPI 1-4 measured input frequency, 100Hz.";
CM_ BO_ 1744 "ECU -> PD16 A output duty/frequency commands, 20Hz base rate. Mux byte = IO type (bits 7-5) | IO index (bits 3-0): type 0 = 25A HCO, 1 = 8A HCO, 2 = half bridge.";
CM_ BO_ 1745 "ECU -> PD16 A output and input pin configuration, 2Hz. Mux types: 0 = 25A HCO, 1 = 8A HCO, 2 = half bridge, 3 = SPI, 4 = AVI.";
CM_ BO_ 1746 "ECU -> PD16 A system configuration, 2Hz. Not observed on this bus yet.";
CM_ BO_ 1747 "PD16 A input state/voltage/duty/frequency, 20Hz base rate. Mux types: 3 = SPI, 4 = AVI (PD16 has no DPI or button inputs).";
CM_ BO_ 1748 "PD16 A output load/voltage/current and fault state, 5Hz base rate. Mux types: 0 = 25A HCO, 1 = 8A HCO, 2 = half bridge. On 8A muxes 1-4 bytes 7 carries the matching 25A HCO retry count / pin state.";
CM_ BO_ 1749 "PD16 A device status and firmware version, 2Hz.";
CM_ BO_ 1750 "PD16 A rail voltages, temperatures, total current and serial, 2Hz. Plain mux 0-5 in byte 0.";
CM_ BO_ 396 "CANopen TPDO1 from the 15-button (3x5) keypad, node ID 12. Sent on button change. Byte 0 bits 0-7 = buttons 1-8, byte 1 bits 0-6 = buttons 9-15 (1 = pressed).";
CM_ BO_ 1804 "CANopen heartbeat from keypad node 12, every 150ms.";
CM_ BO_ 1548 "CANopen SDO download request ECU -> keypad node 12. Observed writing object 0x6200 (digital outputs = button LEDs).";
CM_ BO_ 1420 "CANopen SDO response keypad node 12 -> ECU.";
VAL_ 800 PD16A_AVI_1_STATE 0 "Off" 1 "On" ;
VAL_ 800 PD16A_AVI_2_STATE 0 "Off" 1 "On" ;
VAL_ 800 PD16A_AVI_3_STATE 0 "Off" 1 "On" ;
VAL_ 800 PD16A_AVI_4_STATE 0 "Off" 1 "On" ;
VAL_ 804 PD16A_SPI_1_STATE 0 "Off" 1 "On" ;
VAL_ 804 PD16A_SPI_2_STATE 0 "Off" 1 "On" ;
VAL_ 804 PD16A_SPI_3_STATE 0 "Off" 1 "On" ;
VAL_ 804 PD16A_SPI_4_STATE 0 "Off" 1 "On" ;
VAL_ 1745 PD16A_HCO25_1_CFG_RETRIES 0 "Never" 1 "1" 2 "2" 3 "5" 4 "10" 5 "20" 6 "30" 7 "Always" ;
VAL_ 1745 PD16A_HCO25_1_CFG_DRIVE_TYPE 0 "Undefined" 1 "High Side" 2 "Both" 3 "Open Circuit" ;
VAL_ 1745 PD16A_HCO25_1_CFG_SAFE_STATE 0 "Inactive" 1 "Active" 2 "Open Circuit" ;
VAL_ 1745 PD16A_HCO25_1_CFG_ACTIVE_STATE 0 "Low" 1 "High" ;
VAL_ 1745 PD16A_HCO25_2_CFG_RETRIES 0 "Never" 1 "1" 2 "2" 3 "5" 4 "10" 5 "20" 6 "30" 7 "Always" ;
VAL_ 1745 PD16A_HCO25_2_CFG_DRIVE_TYPE 0 "Undefined" 1 "High Side" 2 "Both" 3 "Open Circuit" ;
VAL_ 1745 PD16A_HCO25_2_CFG_SAFE_STATE 0 "Inactive" 1 "Active" 2 "Open Circuit" ;
VAL_ 1745 PD16A_HCO25_2_CFG_ACTIVE_STATE 0 "Low" 1 "High" ;
VAL_ 1745 PD16A_HCO25_3_CFG_RETRIES 0 "Never" 1 "1" 2 "2" 3 "5" 4 "10" 5 "20" 6 "30" 7 "Always" ;
VAL_ 1745 PD16A_HCO25_3_CFG_DRIVE_TYPE 0 "Undefined" 1 "High Side" 2 "Both" 3 "Open Circuit" ;
VAL_ 1745 PD16A_HCO25_3_CFG_SAFE_STATE 0 "Inactive" 1 "Active" 2 "Open Circuit" ;
VAL_ 1745 PD16A_HCO25_3_CFG_ACTIVE_STATE 0 "Low" 1 "High" ;
VAL_ 1745 PD16A_HCO25_4_CFG_RETRIES 0 "Never" 1 "1" 2 "2" 3 "5" 4 "10" 5 "20" 6 "30" 7 "Always" ;
VAL_ 1745 PD16A_HCO25_4_CFG_DRIVE_TYPE 0 "Undefined" 1 "High Side" 2 "Both" 3 "Open Circuit" ;
VAL_ 1745 PD16A_HCO25_4_CFG_SAFE_STATE 0 "Inactive" 1 "Active" 2 "Open Circuit" ;
VAL_ 1745 PD16A_HCO25_4_CFG_ACTIVE_STATE 0 "Low" 1 "High" ;
VAL_ 1745 PD16A_HCO8_1_CFG_RETRIES 0 "Never" 1 "1" 2 "2" 3 "5" 4 "10" 5 "20" 6 "30" 7 "Always" ;
VAL_ 1745 PD16A_HCO8_1_CFG_DRIVE_TYPE 0 "Undefined" 1 "Undefined" 2 "High Side" 3 "Open Circuit" ;
VAL_ 1745 PD16A_HCO8_1_CFG_SAFE_STATE 0 "Inactive" 1 "Active" 2 "Open Circuit" ;
VAL_ 1745 PD16A_HCO8_1_CFG_ACTIVE_STATE 0 "Low" 1 "High" ;
VAL_ 1745 PD16A_HCO8_2_CFG_RETRIES 0 "Never" 1 "1" 2 "2" 3 "5" 4 "10" 5 "20" 6 "30" 7 "Always" ;
VAL_ 1745 PD16A_HCO8_2_CFG_DRIVE_TYPE 0 "Undefined" 1 "Undefined" 2 "High Side" 3 "Open Circuit" ;
VAL_ 1745 PD16A_HCO8_2_CFG_SAFE_STATE 0 "Inactive" 1 "Active" 2 "Open Circuit" ;
VAL_ 1745 PD16A_HCO8_2_CFG_ACTIVE_STATE 0 "Low" 1 "High" ;
VAL_ 1745 PD16A_HCO8_3_CFG_RETRIES 0 "Never" 1 "1" 2 "2" 3 "5" 4 "10" 5 "20" 6 "30" 7 "Always" ;
VAL_ 1745 PD16A_HCO8_3_CFG_DRIVE_TYPE 0 "Undefined" 1 "Undefined" 2 "High Side" 3 "Open Circuit" ;
VAL_ 1745 PD16A_HCO8_3_CFG_SAFE_STATE 0 "Inactive" 1 "Active" 2 "Open Circuit" ;
VAL_ 1745 PD16A_HCO8_3_CFG_ACTIVE_STATE 0 "Low" 1 "High" ;
VAL_ 1745 PD16A_HCO8_4_CFG_RETRIES 0 "Never" 1 "1" 2 "2" 3 "5" 4 "10" 5 "20" 6 "30" 7 "Always" ;
VAL_ 1745 PD16A_HCO8_4_CFG_DRIVE_TYPE 0 "Undefined" 1 "Undefined" 2 "High Side" 3 "Open Circuit" ;
VAL_ 1745 PD16A_HCO8_4_CFG_SAFE_STATE 0 "Inactive" 1 "Active" 2 "Open Circuit" ;
VAL_ 1745 PD16A_HCO8_4_CFG_ACTIVE_STATE 0 "Low" 1 "High" ;
VAL_ 1745 PD16A_HCO8_5_CFG_RETRIES 0 "Never" 1 "1" 2 "2" 3 "5" 4 "10" 5 "20" 6 "30" 7 "Always" ;
VAL_ 1745 PD16A_HCO8_5_CFG_DRIVE_TYPE 0 "Undefined" 1 "Undefined" 2 "High Side" 3 "Open Circuit" ;
VAL_ 1745 PD16A_HCO8_5_CFG_SAFE_STATE 0 "Inactive" 1 "Active" 2 "Open Circuit" ;
VAL_ 1745 PD16A_HCO8_5_CFG_ACTIVE_STATE 0 "Low" 1 "High" ;
VAL_ 1745 PD16A_HCO8_6_CFG_RETRIES 0 "Never" 1 "1" 2 "2" 3 "5" 4 "10" 5 "20" 6 "30" 7 "Always" ;
VAL_ 1745 PD16A_HCO8_6_CFG_DRIVE_TYPE 0 "Undefined" 1 "Undefined" 2 "High Side" 3 "Open Circuit" ;
VAL_ 1745 PD16A_HCO8_6_CFG_SAFE_STATE 0 "Inactive" 1 "Active" 2 "Open Circuit" ;
VAL_ 1745 PD16A_HCO8_6_CFG_ACTIVE_STATE 0 "Low" 1 "High" ;
VAL_ 1745 PD16A_HCO8_7_CFG_RETRIES 0 "Never" 1 "1" 2 "2" 3 "5" 4 "10" 5 "20" 6 "30" 7 "Always" ;
VAL_ 1745 PD16A_HCO8_7_CFG_DRIVE_TYPE 0 "Undefined" 1 "Undefined" 2 "High Side" 3 "Open Circuit" ;
VAL_ 1745 PD16A_HCO8_7_CFG_SAFE_STATE 0 "Inactive" 1 "Active" 2 "Open Circuit" ;
VAL_ 1745 PD16A_HCO8_7_CFG_ACTIVE_STATE 0 "Low" 1 "High" ;
VAL_ 1745 PD16A_HCO8_8_CFG_RETRIES 0 "Never" 1 "1" 2 "2" 3 "5" 4 "10" 5 "20" 6 "30" 7 "Always" ;
VAL_ 1745 PD16A_HCO8_8_CFG_DRIVE_TYPE 0 "Undefined" 1 "Undefined" 2 "High Side" 3 "Open Circuit" ;
VAL_ 1745 PD16A_HCO8_8_CFG_SAFE_STATE 0 "Inactive" 1 "Active" 2 "Open Circuit" ;
VAL_ 1745 PD16A_HCO8_8_CFG_ACTIVE_STATE 0 "Low" 1 "High" ;
VAL_ 1745 PD16A_HCO8_9_CFG_RETRIES 0 "Never" 1 "1" 2 "2" 3 "5" 4 "10" 5 "20" 6 "30" 7 "Always" ;
VAL_ 1745 PD16A_HCO8_9_CFG_DRIVE_TYPE 0 "Undefined" 1 "Undefined" 2 "High Side" 3 "Open Circuit" ;
VAL_ 1745 PD16A_HCO8_9_CFG_SAFE_STATE 0 "Inactive" 1 "Active" 2 "Open Circuit" ;
VAL_ 1745 PD16A_HCO8_9_CFG_ACTIVE_STATE 0 "Low" 1 "High" ;
VAL_ 1745 PD16A_HCO8_10_CFG_RETRIES 0 "Never" 1 "1" 2 "2" 3 "5" 4 "10" 5 "20" 6 "30" 7 "Always" ;
VAL_ 1745 PD16A_HCO8_10_CFG_DRIVE_TYPE 0 "Undefined" 1 "Undefined" 2 "High Side" 3 "Open Circuit" ;
VAL_ 1745 PD16A_HCO8_10_CFG_SAFE_STATE 0 "Inactive" 1 "Active" 2 "Open Circuit" ;
VAL_ 1745 PD16A_HCO8_10_CFG_ACTIVE_STATE 0 "Low" 1 "High" ;
VAL_ 1745 PD16A_HBO_1_CFG_RETRIES 0 "Never" 1 "1" 2 "2" 3 "5" 4 "10" 5 "20" 6 "30" 7 "Always" ;
VAL_ 1745 PD16A_HBO_1_CFG_DRIVE_TYPE 0 "Low Side" 1 "High Side" 2 "Both" 3 "Open Circuit" ;
VAL_ 1745 PD16A_HBO_1_CFG_SAFE_STATE 0 "Inactive" 1 "Active" 2 "Open Circuit" ;
VAL_ 1745 PD16A_HBO_1_CFG_ACTIVE_STATE 0 "Low" 1 "High" ;
VAL_ 1745 PD16A_HBO_1_CFG_CONTROL_METHOD 0 "Duty Cycle" 1 "Current Control" ;
VAL_ 1745 PD16A_HBO_2_CFG_RETRIES 0 "Never" 1 "1" 2 "2" 3 "5" 4 "10" 5 "20" 6 "30" 7 "Always" ;
VAL_ 1745 PD16A_HBO_2_CFG_DRIVE_TYPE 0 "Low Side" 1 "High Side" 2 "Both" 3 "Open Circuit" ;
VAL_ 1745 PD16A_HBO_2_CFG_SAFE_STATE 0 "Inactive" 1 "Active" 2 "Open Circuit" ;
VAL_ 1745 PD16A_HBO_2_CFG_ACTIVE_STATE 0 "Low" 1 "High" ;
VAL_ 1745 PD16A_HBO_2_CFG_CONTROL_METHOD 0 "Duty Cycle" 1 "Current Control" ;
VAL_ 1745 PD16A_SPI_1_CFG_PIN_MODE 0 "Reluctor" 1 "Hall Effect" 2 "Custom" ;
VAL_ 1745 PD16A_SPI_1_CFG_STARTUP_STATE 0 "Off" 1 "On" 2 "Last State" ;
VAL_ 1745 PD16A_SPI_1_CFG_INPUT_MODE 0 "Push On Push Off" 1 "Momentary" ;
VAL_ 1745 PD16A_SPI_1_CFG_PULLUP 0 "Disable" 1 "Enable" ;
VAL_ 1745 PD16A_SPI_1_CFG_EDGE_SELECT 0 "Falling" 1 "Rising" ;
VAL_ 1745 PD16A_SPI_2_CFG_PIN_MODE 0 "Reluctor" 1 "Hall Effect" 2 "Custom" ;
VAL_ 1745 PD16A_SPI_2_CFG_STARTUP_STATE 0 "Off" 1 "On" 2 "Last State" ;
VAL_ 1745 PD16A_SPI_2_CFG_INPUT_MODE 0 "Push On Push Off" 1 "Momentary" ;
VAL_ 1745 PD16A_SPI_2_CFG_PULLUP 0 "Disable" 1 "Enable" ;
VAL_ 1745 PD16A_SPI_2_CFG_EDGE_SELECT 0 "Falling" 1 "Rising" ;
VAL_ 1745 PD16A_SPI_3_CFG_PIN_MODE 0 "Reluctor" 1 "Hall Effect" 2 "Custom" ;
VAL_ 1745 PD16A_SPI_3_CFG_STARTUP_STATE 0 "Off" 1 "On" 2 "Last State" ;
VAL_ 1745 PD16A_SPI_3_CFG_INPUT_MODE 0 "Push On Push Off" 1 "Momentary" ;
VAL_ 1745 PD16A_SPI_3_CFG_PULLUP 0 "Disable" 1 "Enable" ;
VAL_ 1745 PD16A_SPI_3_CFG_EDGE_SELECT 0 "Falling" 1 "Rising" ;
VAL_ 1745 PD16A_SPI_4_CFG_PIN_MODE 0 "Reluctor" 1 "Hall Effect" 2 "Custom" ;
VAL_ 1745 PD16A_SPI_4_CFG_STARTUP_STATE 0 "Off" 1 "On" 2 "Last State" ;
VAL_ 1745 PD16A_SPI_4_CFG_INPUT_MODE 0 "Push On Push Off" 1 "Momentary" ;
VAL_ 1745 PD16A_SPI_4_CFG_PULLUP 0 "Disable" 1 "Enable" ;
VAL_ 1745 PD16A_SPI_4_CFG_EDGE_SELECT 0 "Falling" 1 "Rising" ;
VAL_ 1745 PD16A_AVI_1_CFG_STARTUP_STATE 0 "Off" 1 "On" 2 "Last State" ;
VAL_ 1745 PD16A_AVI_1_CFG_INPUT_MODE 0 "Push On Push Off" 1 "Momentary" ;
VAL_ 1745 PD16A_AVI_1_CFG_PULLUP 0 "Disable" 1 "Enable 1k" 2 "Enable 240R" ;
VAL_ 1745 PD16A_AVI_2_CFG_STARTUP_STATE 0 "Off" 1 "On" 2 "Last State" ;
VAL_ 1745 PD16A_AVI_2_CFG_INPUT_MODE 0 "Push On Push Off" 1 "Momentary" ;
VAL_ 1745 PD16A_AVI_2_CFG_PULLUP 0 "Disable" 1 "Enable 1k" 2 "Enable 240R" ;
VAL_ 1745 PD16A_AVI_3_CFG_STARTUP_STATE 0 "Off" 1 "On" 2 "Last State" ;
VAL_ 1745 PD16A_AVI_3_CFG_INPUT_MODE 0 "Push On Push Off" 1 "Momentary" ;
VAL_ 1745 PD16A_AVI_3_CFG_PULLUP 0 "Disable" 1 "Enable 1k" 2 "Enable 240R" ;
VAL_ 1745 PD16A_AVI_4_CFG_STARTUP_STATE 0 "Off" 1 "On" 2 "Last State" ;
VAL_ 1745 PD16A_AVI_4_CFG_INPUT_MODE 0 "Push On Push Off" 1 "Momentary" ;
VAL_ 1745 PD16A_AVI_4_CFG_PULLUP 0 "Disable" 1 "Enable 1k" 2 "Enable 240R" ;
VAL_ 1746 PD16A_ECR_STATUS 0 "Off" 1 "On" ;
VAL_ 1746 PD16A_CAN_POWER 0 "Disabled" 1 "Enabled" ;
VAL_ 1746 PD16A_CAN_TERMINATION 0 "Disabled" 1 "Enabled" ;
VAL_ 1747 PD16A_SPI_1_IN_STATE 0 "Off" 1 "On" ;
VAL_ 1747 PD16A_SPI_2_IN_STATE 0 "Off" 1 "On" ;
VAL_ 1747 PD16A_SPI_3_IN_STATE 0 "Off" 1 "On" ;
VAL_ 1747 PD16A_SPI_4_IN_STATE 0 "Off" 1 "On" ;
VAL_ 1747 PD16A_AVI_1_IN_STATE 0 "Off" 1 "On" ;
VAL_ 1747 PD16A_AVI_2_IN_STATE 0 "Off" 1 "On" ;
VAL_ 1747 PD16A_AVI_3_IN_STATE 0 "Off" 1 "On" ;
VAL_ 1747 PD16A_AVI_4_IN_STATE 0 "Off" 1 "On" ;
VAL_ 1748 PD16A_HCO8_1_PIN_STATE 0 "Operational" 1 "High Current" 2 "Over Current" 3 "Short Circuit" 4 "Open Circuit" 5 "Invalid Pin Selection" 6 "Unexpected Profile" 7 "Disabled" ;
VAL_ 1748 PD16A_HCO25_1_PIN_STATE 0 "Operational" 1 "High Current" 2 "Over Current" 3 "Short Circuit" 4 "Open Circuit" 5 "Invalid Pin Selection" 6 "Unexpected Profile" 7 "Disabled" ;
VAL_ 1748 PD16A_HCO8_2_PIN_STATE 0 "Operational" 1 "High Current" 2 "Over Current" 3 "Short Circuit" 4 "Open Circuit" 5 "Invalid Pin Selection" 6 "Unexpected Profile" 7 "Disabled" ;
VAL_ 1748 PD16A_HCO25_2_PIN_STATE 0 "Operational" 1 "High Current" 2 "Over Current" 3 "Short Circuit" 4 "Open Circuit" 5 "Invalid Pin Selection" 6 "Unexpected Profile" 7 "Disabled" ;
VAL_ 1748 PD16A_HCO8_3_PIN_STATE 0 "Operational" 1 "High Current" 2 "Over Current" 3 "Short Circuit" 4 "Open Circuit" 5 "Invalid Pin Selection" 6 "Unexpected Profile" 7 "Disabled" ;
VAL_ 1748 PD16A_HCO25_3_PIN_STATE 0 "Operational" 1 "High Current" 2 "Over Current" 3 "Short Circuit" 4 "Open Circuit" 5 "Invalid Pin Selection" 6 "Unexpected Profile" 7 "Disabled" ;
VAL_ 1748 PD16A_HCO8_4_PIN_STATE 0 "Operational" 1 "High Current" 2 "Over Current" 3 "Short Circuit" 4 "Open Circuit" 5 "Invalid Pin Selection" 6 "Unexpected Profile" 7 "Disabled" ;
VAL_ 1748 PD16A_HCO25_4_PIN_STATE 0 "Operational" 1 "High Current" 2 "Over Current" 3 "Short Circuit" 4 "Open Circuit" 5 "Invalid Pin Selection" 6 "Unexpected Profile" 7 "Disabled" ;
VAL_ 1748 PD16A_HCO8_5_PIN_STATE 0 "Operational" 1 "High Current" 2 "Over Current" 3 "Short Circuit" 4 "Open Circuit" 5 "Invalid Pin Selection" 6 "Unexpected Profile" 7 "Disabled" ;
VAL_ 1748 PD16A_HCO8_6_PIN_STATE 0 "Operational" 1 "High Current" 2 "Over Current" 3 "Short Circuit" 4 "Open Circuit" 5 "Invalid Pin Selection" 6 "Unexpected Profile" 7 "Disabled" ;
VAL_ 1748 PD16A_HCO8_7_PIN_STATE 0 "Operational" 1 "High Current" 2 "Over Current" 3 "Short Circuit" 4 "Open Circuit" 5 "Invalid Pin Selection" 6 "Unexpected Profile" 7 "Disabled" ;
VAL_ 1748 PD16A_HCO8_8_PIN_STATE 0 "Operational" 1 "High Current" 2 "Over Current" 3 "Short Circuit" 4 "Open Circuit" 5 "Invalid Pin Selection" 6 "Unexpected Profile" 7 "Disabled" ;
VAL_ 1748 PD16A_HCO8_9_PIN_STATE 0 "Operational" 1 "High Current" 2 "Over Current" 3 "Short Circuit" 4 "Open Circuit" 5 "Invalid Pin Selection" 6 "Unexpected Profile" 7 "Disabled" ;
VAL_ 1748 PD16A_HCO8_10_PIN_STATE 0 "Operational" 1 "High Current" 2 "Over Current" 3 "Short Circuit" 4 "Open Circuit" 5 "Invalid Pin Selection" 6 "Unexpected Profile" 7 "Disabled" ;
VAL_ 1748 PD16A_HBO_1_PIN_STATE 0 "Operational" 1 "High Current" 2 "Over Current" 3 "Short Circuit" 4 "Open Circuit" 5 "Invalid Pin Selection" 6 "Unexpected Profile" 7 "Disabled" ;
VAL_ 1748 PD16A_HBO_2_PIN_STATE 0 "Operational" 1 "High Current" 2 "Over Current" 3 "Short Circuit" 4 "Open Circuit" 5 "Invalid Pin Selection" 6 "Unexpected Profile" 7 "Disabled" ;
VAL_ 1749 PD16A_STATUS 0 "Boot Mode" 1 "In Firmware" 2 "Hardware Failure" 3 "Firmware Erased" 4 "Watchdog Timeout" 5 "Illegal Opcode" ;
VAL_ 1750 PD16A_IGNITION_SWITCH 0 "Off" 1 "On" ;
VAL_ 1750 PD16A_HCO25_34_TEMP_STATUS 0 "OK" 1 "Warning >115C" 2 "Shutdown >145C" ;
VAL_ 1750 PD16A_HCO25_12_TEMP_STATUS 0 "OK" 1 "Warning >115C" 2 "Shutdown >145C" ;
VAL_ 1750 PD16A_TVS_TEMP_STATUS 0 "OK" 1 "Warning >115C" 2 "Shutdown >145C" ;
VAL_ 1750 PD16A_MAIN_RAIL_TEMP_STATUS 0 "OK" 1 "Warning >115C" 2 "Shutdown >145C" ;
VAL_ 1804 KEYPAD_NMT_STATE 0 "Boot-up" 4 "Stopped" 5 "Operational" 127 "Pre-operational" ;
